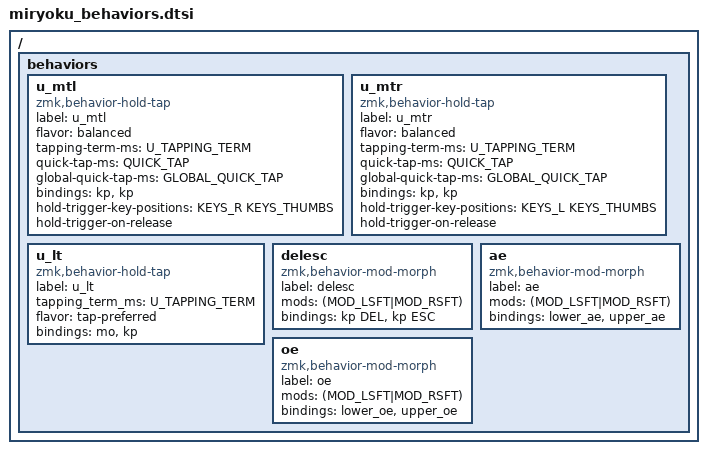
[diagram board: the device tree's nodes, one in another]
// Copyright 2022 Manna Harbour
// https://github.com/manna-harbour/miryoku

/*            KEY POSITIONS
  ╭────────────────╮ ╭────────────────╮
  │  1  2  3  4  5 │ │  6  7  8  9 10 │
  │ 13 14 15 16 17 │ │ 18 19 20 21 22 │
  │ 25 26 27 28 29 │ │ 30 31 32 33 34 │
  ╰─────╮ 36 37 38 │ │ 39 40 41 ╭─────╯
        ╰──────────╯ ╰──────────╯      */

#define KEYS_L 1 2 3 4 5 13 14 15 16 17 25 26 27 28 29
#define KEYS_R 6 7 8 9 10 18 19 20 21 22 30 31 32 33 34
#define KEYS_THUMBS 36 37 38 39 40 41

/ {
  behaviors {
    u_mtl: u_mtl {
      compatible = "zmk,behavior-hold-tap";
      label = "u_mtl";
      #binding-cells = <2>;
      flavor = "balanced";
      tapping-term-ms = <U_TAPPING_TERM>;
      quick-tap-ms = <QUICK_TAP>;
      global-quick-tap-ms = <GLOBAL_QUICK_TAP>;
      bindings = <&kp>, <&kp>;
      hold-trigger-key-positions = <KEYS_R KEYS_THUMBS>;
      hold-trigger-on-release;
    };
    u_mtr: u_mtr {
      compatible = "zmk,behavior-hold-tap";
      label = "u_mtr";
      #binding-cells = <2>;
      flavor = "balanced";
      tapping-term-ms = <U_TAPPING_TERM>;
      quick-tap-ms = <QUICK_TAP>;
      global-quick-tap-ms = <GLOBAL_QUICK_TAP>;
      bindings = <&kp>, <&kp>;
      hold-trigger-key-positions = <KEYS_L KEYS_THUMBS>;
      hold-trigger-on-release;
    };
    u_lt: u_lt {
      compatible = "zmk,behavior-hold-tap";
      label = "u_lt";
      #binding-cells = <2>;
      tapping_term_ms = <U_TAPPING_TERM>;
      flavor = "tap-preferred";
      bindings = <&mo>, <&kp>;
    };
    delesc: delesc {
        compatible = "zmk,behavior-mod-morph";
        label = "delesc";
        #binding-cells = <0>;
        mods = <(MOD_LSFT|MOD_RSFT)>;
        bindings = <&kp DEL>, <&kp ESC>;
    };
    ae: ae {
        compatible = "zmk,behavior-mod-morph";
        label = "ae";
        #binding-cells = <0>;
        mods = <(MOD_LSFT|MOD_RSFT)>;
        bindings = <&lower_ae>, <&upper_ae>;
    };
    oe: oe {
        compatible = "zmk,behavior-mod-morph";
        label = "oe";
        #binding-cells = <0>;
        mods = <(MOD_LSFT|MOD_RSFT)>;
        bindings = <&lower_oe>, <&upper_oe>;
    };
  };
};
